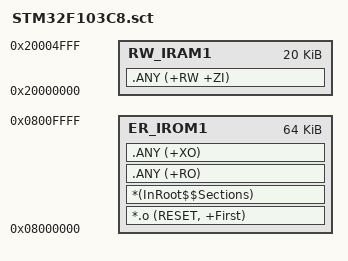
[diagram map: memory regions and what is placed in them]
; ================================================================
;  STM32F103C8T6 分散加载描述文件（scatter file）
;  ----------------------------------------------------------------
;  之前 Keil / EIDE 都没给链接器指定 ROM 起始地址，
;  armlink 就用了默认值 0x00008000，导致烧录时找不到 Flash 算法。
;  本文件把代码固定在 Flash 0x08000000，RAM 固定在 0x20000000。
;
;  硬件规格：64KB Flash (0x08000000 ~ 0x0800FFFF)
;            20KB SRAM  (0x20000000 ~ 0x20004FFF)
; ================================================================

LR_IROM1 0x08000000 0x00010000  {        ; 加载区：64KB Flash
  ER_IROM1 0x08000000 0x00010000  {      ; 执行区：代码 + 只读数据
    *.o (RESET, +First)
    *(InRoot$$Sections)
    .ANY (+RO)
    .ANY (+XO)
  }

  RW_IRAM1 0x20000000 0x00005000  {      ; 执行区：可读写 + 零初始化数据
    .ANY (+RW +ZI)
  }
}
